AUTOSAR XML (schema 4-2-1)
package /RootP_ASWC_DISPATCH_CORE1_AppASILB
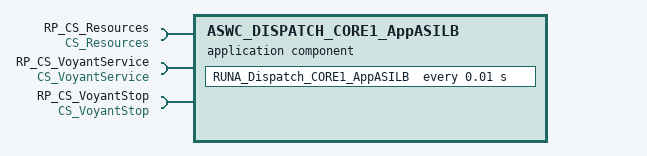
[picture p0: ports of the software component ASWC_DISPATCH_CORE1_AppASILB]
  application sw component type ASWC_DISPATCH_CORE1_AppASILB
    require port RP_CS_Resources: client-com-spec=Request, required-interface=CS_Resources
    require port RP_CS_VoyantService: client-com-spec=Piloter, required-interface=CS_VoyantService
    require port RP_CS_VoyantStop: client-com-spec=Piloter, required-interface=CS_VoyantStop
    behavior IB_ASWC_DISPATCH_CORE1_AppASILB: handle-termination-and-restart=NO-SUPPORT
      timing event RUNA_Dispatch_Cyclic: start-on-event=RUNA_Dispatch_CORE1_AppASILB, period=0.01
      runnable RUNA_Dispatch_CORE1_AppASILB: can-be-invoked-concurrently=true
        sync call scp_Resources_Request: operation=RP_CS_Resources.Request, timeout=0.0
        sync call scp_VoyantService_Piloter: operation=RP_CS_VoyantService.Piloter, timeout=0.0
        sync call scp_VoyantStop_Piloter: operation=RP_CS_VoyantStop.Piloter, timeout=0.0
  swc implementation ASWC_DISPATCH_CORE1_AppASILB_Impl: programming-language=C, sw-version=1.0.0, vendor-id=0, behavior=IB_ASWC_DISPATCH_CORE1_AppASILB
    code-descriptors:
      code SRC: artifact-descriptors=autosar-engineering-object={short-label=EngObject, category=SWSRC}
    resource consumption Resources
      memory section CODE: sw-addrmethod=CODE_ASWC_DISPATCH_CORE1_AppASILB
  sw addr method CODE_ASWC_DISPATCH_CORE1_AppASILB: memory-allocation-keyword-policy=ADDR-METHOD-SHORT-NAME-AND-ALIGNMENT, section-type=CODE
